# Polarfire SoC register map
Vendor: Microchip; File version: 1.0
CPU: Microchip PolarFire SoC 1.0, little endian
Registers are 32-bit, read-write, reset 0x0 unless marked. A register's access mark holds for its fields unless they carry their own. Offsets are from the block's base; [hi:lo] are bit positions.

## MMUART0_LO — MMUART0_LO Controller
Base 0x20000000
Same registers: MMUART1_LO 0x20100000, MMUART2_LO 0x20102000, MMUART3_LO 0x20104000, MMUART4_LO 0x20106000, MMUART0_HI 0x28000000, MMUART1_HI 0x28100000, MMUART2_HI 0x28102000, MMUART3_HI 0x28104000, MMUART4_HI 0x28106000
0x00 RBR ro — Receiver buffer register
  [7:0] RBR — This register holds the receive data bits for MMUART_x. The default value is unknown since the register is loaded with data in the receive FIFO. Bit 0 is the LSB and it is the first bit received. It may be configured as the MSB by configuring the E_MSB_RX bit in the MM1. The divisor latch access bit (DLAB).. bit 7 of LCR.. must be 0 to read this register. This register is read only. Writing to this register with the DLAB 0 changes the transmit holding register (THR) register value.
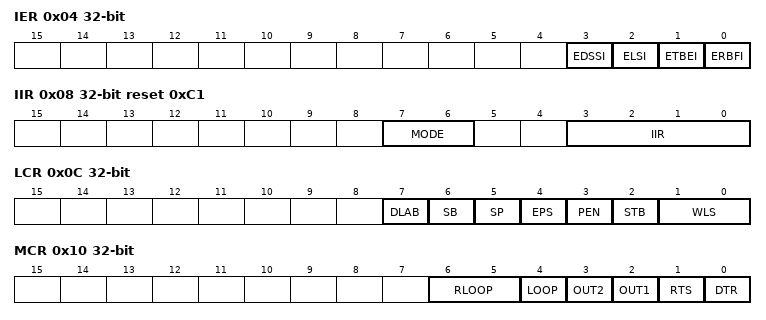
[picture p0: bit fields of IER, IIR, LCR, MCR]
0x04 IER — Interrupt enable register
  [3] EDSSI — Modem status interrupt enable 0: Disabled (default) 1: Enabled
  [2] ELSI — Receiver line status interrupt enable 0: Disabled (default) 1: Enabled
  [1] ETBEI — Transmitter holding register empty interrupt enable 0: Disabled (default) 1: Enabled
  [0] ERBFI — Enables received data available interrupt 0: Disabled (default) 1: Enabled
0x08 IIR ro reset 0xC1 — Interrupt identification register
  [7:6] MODE — Always 0b11. Enables FIFO mode.
  [3:0] IIR — Interrupt identification bits. 0b0110: Highest priority. Receiver line status interrupts due to overrun error.. parity error.. framing error.. or break interrupt. Reading the line status register resets this interrupt. 0b0100: Second priority. Receive data available interrupt modem status interrupt. Reading the receiver buffer register (RBR) or the FIFO drops below the trigger level resets this interrupt. 0b1100: Second priority. Character timeout indication interrupt occurs when no characters have been read from the Rx FIFO during the last four character times and there was at least one character in it during this time. Reading the RBR resets this interrupt. 0b0010: Third priority. Transmit holding register empty interrupt. Reading the IIR or writing to the transmit holding register (THR) resets the interrupt. 0b0000: Fourth priority. Modem status interrupt due to clear to send.. data set ready.. ring indicator.. or data carrier detect being asserted. Reading the modem status register resets this interrupt. 0b0011: Fifth priority. Multi-mode interrupts can occur due to any of the interrupts mentioned in IIM. For more details refer to Table 12-15.
0x0C LCR — Line control register
  [7] DLAB — Divisor latch access bit. Enables access to the divisor latch registers during read or write operation to address 0 and 1. 0: Disabled (default) 1: Enabled
  [6] SB — Set break. Enabling this bit sets MMUART_x_TXD to 0. This does not have any effect on transmitter logic. The break is disabled by setting the bit to 0. 0: Disabled (default) 1: Set break
  [5] SP — Stick parity 0: Disabled (default) 1: Enabled When stick parity is enabled.. the parity is set according to bits [4:3] as follows: 11: 0 will be sent as a parity bit and checked when receiving. 01: 1 will be sent as a parity bit and checked when receiving.
  [4] EPS — Even parity select 0: Odd parity (default) 1: Even parity
  [3] PEN — Parity enable 0: Disabled 1: Enabled. Parity is added in transmission and checked in receiving.
  [2] STB — Number of stop bits (STB) 0: 1 stop bit (default) 1: 11/2 stop bits when WLS=00 The number of stop bits is 2 for all other cases not described above (STB=1 and WLS=01.. 10.. or 11).
  [1:0] WLS — Word length select 0b00: 5 bits (default) 0b01: 6 bits 0b10: 7 bits 0b11: 8 bits
0x10 MCR — Modem control register
  [6:5] RLOOP — Remote loopback enable bits. In the Remote loopback mode.. when a bit is received.. it is sent directly out the transmit line.. bypassing the transmitter block.. and disabling the receiver. In the Automatic echo mode.. when a bit is received.. it is sent directly out the transmit line.. bypassing the transmitter block.. while the receiver is still enabled. 00: Disabled (default) 01: Remote loopback enabled 10: Automatic echo enabled 11: Reserved Note: Local loopback mode has priority over the remote/echo loopback modes.
  [4] LOOP — In the Loopback mode.. MMUART_x_TXD is set to 1. The MMUART_x_RXD.. MMUART_x_DSR.. MMUART_x_CTS.. MMUART_x_RI.. and MMUART_x_DCD inputs are disconnected. The output of the transmitter shift register is looped back into the receiver shift register. The modem control outputs (MMUART_x_DTR.. MMUART_x_RTS.. MMUART_x_OUT1.. and MMUART_x_OUT2) are connected internally to the modem control inputs.. and the modem control output pins are set as 1. The transmitted data is immediately received.. allowing Cortex-M3 processor to check the operation of the MMUART_x. The interrupts are operating in the Loopback mode. 0: Disabled (default) 1: Local loopback enabled Note: The local loopback mode has priority over the remote loopback modes. LOOPBACK is only implemented in basic UART mode. It does function in LIN IRDA or Smart card modes.
  [3] OUT2 — Controls the output2 (OUT2) signal. Active Low 0: OUT2n is less than equal to 1 (default) 1: OUT2n is less than equal to 0
  [2] OUT1 — Controls the output1 (OUT1) signal. Active Low 0: OUT1n is less than equal to 1 (default) 1: OUT1n is less than equal to 0
  [1] RTS — Controls the request to send (MMUART_x_RTS) signal. Active Low 0: RTSn is less than equal to 1 (default) 1: RTSn is less than equal to 0
  [0] DTR — Data terminal ready (MMUART_x_DTR) output. Active Low 0: DTRn is less than or equal to 1 (default) 1: DTRn is less than or equal to 0
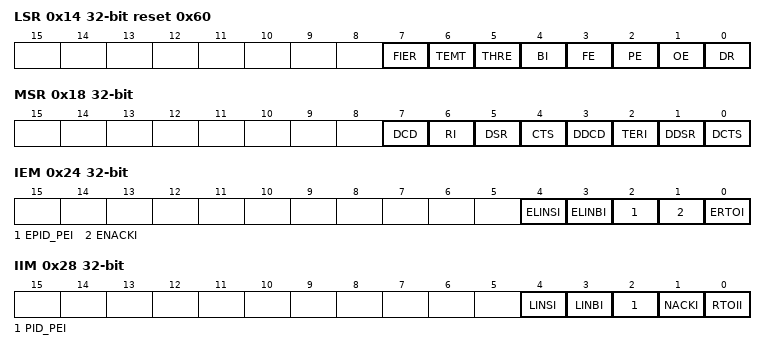
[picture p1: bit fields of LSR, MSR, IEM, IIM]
0x14 LSR ro reset 0x60 — Line status register
  [7] FIER — This bit is set when there is at least one parity error.. framing error.. or break indication in the FIFO. FIER is cleared when Cortex-M3 processor reads the LSR.. if there are no subsequent errors in the FIFO.
  [6] TEMT — Transmit empty (TEMT). This bit is set to 1 when both the transmitter FIFO and shift registers are empty.
  [5] THRE — Transmitter holding register empty (THRE). Indicates that the MMUART_x is ready to transmit a new data byte. THRE causes an interrupt to the Cortex-M3 processor when bit 1 (ETBEI) in the interrupt enable register is 1. This bit is set when the Tx FIFO is empty. It is cleared when at least one byte is written to the Tx FIFO.
  [4] BI — Break interrupt (BI). Indicates that the receive data is at 0 longer than a full word transmission time (start bit + data bits + parity + stop bits). BI is cleared when Cortex-M3 processor reads the line status register (LSR). This error is revealed to the Cortex-M3 processor when it is associated character is at the top of the FIFO. When break occurs.. only one zero character is loaded into the FIFO.
  [3] FE — Framing error (FE). Indicates that the receive byte did not have a valid stop bit. FE is cleared when Cortex-M3 processor reads the LSR. The MMUART_x tries to resynchronize after a framing error. To do this.. it assumes that the framing error was due to the next start bit.. so it samples this start bit twice.. and then starts receiving the data. This error is revealed to Cortex-M3 processor when it is associated character is at the top of the FIFO.
  [2] PE — Parity error (PE). Indicates that the receive byte had a parity error. PE is cleared when the Cortex-M3 processor reads the LSR. This error is revealed to the Cortex-M3 processor when it is associated character is at the top of the FIFO.
  [1] OE — Overrun error (OE). Indicates that the new byte was received before the Cortex-M3 processor reads the byte from the receive buffer.. and that the earlier data byte was destroyed. OE is cleared when the Cortex-M3 processor reads the LSR. If the data continues to fill the FIFO beyond the trigger level.. an overrun error occurs once the FIFO is full and the next character has been completely received in the shift register. The character in the shift register is overwritten.. but it is not transferred to the FIFO.
  [0] DR — Data ready (DR). 1: Indicates when a data byte is received and stored in the receive buffer or the FIFO. DR is cleared to 0 when the Cortex-M3 processor reads the data from the receive buffer or the FIFO.
0x18 MSR ro — Modem status register
  [7] DCD — Data carrier detect (DCD) (MMUART_x_DCD).The complement of DCD input. When bit 4 of the MCR is set to 1 (loop).. this bit is equivalent to OUT2 in the MCR.
  [6] RI — Ring indicator (RI) (MMUART_x_RI). The complement of the RI input. When bit 4 of the MCR is set to 1 (loop).. this bit is equivalent to OUT1 in the MCR.
  [5] DSR — Data set ready (DSR) (MMUART_x_DSR). The complement of the DSR input. When bit 4 of the MCR is set to 1 (loop).. this bit is equivalent to RTS in the MCR.
  [4] CTS — Clear to send (CTS) (MMUART_x_CTS). The complement of the CTS input. When bit 4 of the MCR is set to 1 (loop).. this bit is equivalent to DTR in the MCR.
  [3] DDCD — Delta data carrier detect (DDCD) indicator. Indicates that DCD input has changed state. Whenever bit 0.. 1.. 2.. or 3 is set to 1.. a modem status interrupt is generated.
  [2] TERI — Trailing edge of ring indicator (TERI) detector. Indicates that RI input has changed from 0 to 1. Whenever bit 0.. 1.. 2.. or 3 is set to 1.. a modem status interrupt is generated.
  [1] DDSR — Delta data set ready (DDSR) indicator. Indicates that the DSRn input has changed state since the last time it was read by the Cortex-M3 processor. Whenever bit 0.. 1.. 2.. or 3 is set to 1.. a modem status interrupt is generated.
  [0] DCTS — Delta clear to send (DCTS) indicator. Indicates that the CTSn input has changed state since the last time it was read by the Cortex-M3 processor. Whenever bit 0.. 1.. 2.. or 3 is set to 1.. a modem status interrupt is generated.
0x1C SR — Scratch register
  [7:0] SCR — Scratch register. This register has no effect on MMUART_x operation.
0x24 IEM — Multi-mode interrupt enable register
  [4] ELINSI — Enables the LIN sync detection interrupt. 0: Disabled (default) 1: Enabled
  [3] ELINBI — Enables LIN break interrupt. 0: Disabled (default) 1: Enabled
  [2] EPID_PEI — Enables PID parity error interrupt 0: Disabled (default) 1: Enabled
  [1] ENACKI — Enables NACK interrupt. 0: Disabled (default) 1: Enabled
  [0] ERTOI — Enables receiver timeout interrupt. 0: Disabled (default) 1: Enabled
0x28 IIM ro — Multi-mode interrupt identification register
  [4] LINSI rw — LIN sync detection interrupt ID. This bit set when 5th falling edge is detected by the sync timer. It resets the FIFO address pointers so that the PID will be in the first location. Reading the IIM register clears this interrupt.
  [3] LINBI rw — LIN break interrupt.. set automatically when break length of 11.5 Tbits is detected. Reading the IIM register clears this interrupt.
  [2] PID_PEI — Protected identifier field (PID) parity error interrupt is generated when there is a mismatch in PID in LIN header.. that is.. when either the P0 or P1 bits in the incoming PID byte do not match the calculated P0 and P1 error.
  [1] NACKI rw — NACK interrupt is asserted when EERR bit is set in MM2. Reading the MM2 clears the interrupt.
  [0] RTOII — Receiver time-out (RTO) interrupt ID. RTO interrupt is asserted when RTO value is reached by the counter. It gets cleared when writing to the RTO register.
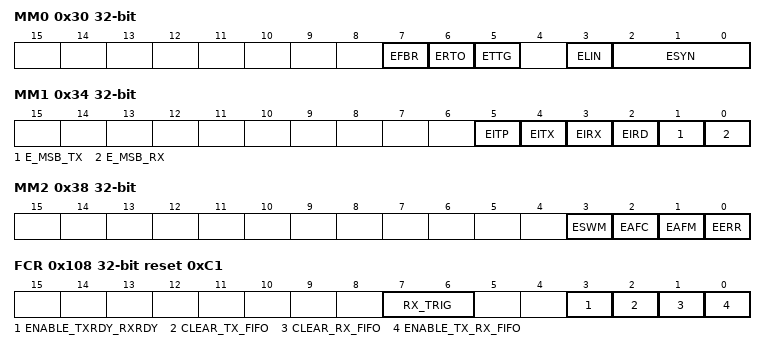
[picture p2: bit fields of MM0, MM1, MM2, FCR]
0x30 MM0 — Multi-mode control register0
  [7] EFBR — Enable fractional baud rate (FBR) mode. 0: Disabled (default) 1: Enabled
  [6] ERTO — Enable receiver timeout (RTO). Writing this bit enables the timeout and restarts the counter value. The timeout value is determined by the RTO register. 0: Disabled (default) 1: Enabled
  [5] ETTG — Enable transmitter time guard (TTG). The time guard value is determined by the TTG Register. 0: Disabled (default) 1: Enabled
  [3] ELIN — Enable LIN header detection and automatic baud rate calculation. 0: Disabled (default) 1: Enabled
  [2:0] ESYN — Enable synchronous operation. There are four types of Synchronous Operation modes that can be enabled. 0b000: Disabled.. that is.. Asynchronous mode (default) 0b001: Synchronous slave enabled.. positive-edge clock 0b010: Synchronous slave enabled.. negative-edge clock 0b011: Synchronous master enabled.. positive-edge clock 0b100: Synchronous master enabled.. negative-edge clock 0b101.. 0b110.. and 0b111: Reserved
0x34 MM1 — Multi-mode control register1
  [5] EITP — Output pulse width for RZI mod can be modified using this bit. 0: 3/16th Tbit pulse width (default). 1: 1/4th Tbit pulse width.
  [4] EITX — You can configure output polarity for RZI modulation. 0: RZI output pulses are active Low and signify a low NRZ value (default). 1: RZI output pulses are active High and signify a high NRZ value.
  [3] EIRX — You can configure input polarity for RZI demodulation. 0: RZI input pulses are active Low.. signifying a low NRZ value (default). 1: RZI input pulses are active High.. signifying a high NRZ value.
  [2] EIRD — Enables RZI modulation/demodulation. 0: Disabled (default) 1: Enabled
  [1] E_MSB_TX — LSB or MSB can be sent first by configuring this bit. By default.. the "THR" bit 0 is the LSB.. and is the first transmitted bit. Bit 0 of the THR may be configured as the last transmitted bit.. MSB. 0: THR's bit 0 is the first transmitted bit.(LSB). (default). 1: THR's bit 0 is the last transmitted bit.(MSB).
  [0] E_MSB_RX — LSB or MSB can be received first by configuring this bit. By default.. the receiver buffer register's (RBR) bit 0 is the LSB.. and is the first received bit. Bit 0 of the RBR may be configured as the last received bit.. MSB. 0: RBR's bit 0 is the first received bit(LSB). (default). 1: RBR's bit 0 is the last received bit(MSB).
0x38 MM2 — Multi-mode control register2
  [3] ESWM — Enable single-wire.. half-duplex mode. 0: Disabled (default) 1: Enabled
  [2] EAFC — Enable a address flag clear (EAFC). When EAFM is enabled the Rx FIFO is disabled until another address flag with matching address is received. The bit gets cleared on write in multi-mode control registers 2. 0: Disabled (default) 1: Enabled
  [1] EAFM — Enable automatic 9-bit address flag mode (EAFM). It should be noted that for enabling this bit it requires.. the LCR should be in an 8-bit and stick parity (SP) bit configured to 0. If EAFM bit is disabled.. the Rx FIFO is enabled by receiving all the bytes. When EAFM bit is enabled.. the Rx FIFO is disabled until an address flag with matching address is received. Note: If an address match occurs and the Rx FIFO is enabled then it can be disabled.. if either another address flag occurs or there is a mismatch or the EAFC bit is set. In either case.. the Address flag compare will continue as long as the EAFM bit is set. 0: Disabled (default) 1: Enabled
  [0] EERR — When the EERR bit is set.. the receiver forces an error signal transmit out.. if an incoming parity error is detected. Error signal (ACK/NACK) is sent during stop time enable. Note: The EERR only applies in an 8-bit data length.. 2 stop bit configuration. Error signal occurs during the last 1.5 stop bits as per Figure 12-18 on page 529. 0: Disabled (default) 1: Enabled
0x3C DFR — Fractional divisor register
  [5:0] DFR — The fractional divisor register (DFR) is used to store the fractional divisor used to calculate the fractional baud rate value in 1/64th using EQ 5. 0x0: 0/64 0x1: 1/64 .... 0x3F: 63/64
0x44 GFR — Glitch filter register
  [2:0] GLR — The glitch filter resynchronizes (GLR) and suppresses random input noise from MMUART_x_RXD (serial input data) and MMUART_x_SCK_IN (serial input clock in synchronous mode) based on the filter length given in number system clock cycles. The following are the different filter lengths in the APB clock cycles that can be written into the GLR register and their description. 0b000: Two resynchronize flip-flops are used but there is no spike suppression. 0b001: Three resynchronize flip-flops are used but there is no spike suppression. 0b010: Three resynchronize flip-flops are used and it also causes 1 APB clock cycle suppression. 0b011: Three resynchronize flip-flops are used and it also causes 2 APB clock cycle suppression. 0b100: Three resynchronize flip-flops are used and it also causes 3 APB clock cycle suppression. 0b101: Three resynchronize flip-flops are used and it also causes 4 APB clock cycle suppression. 0b110: Three resynchronize flip-flops are used and it also causes 5 APB clock cycle suppression. 0b111: Three resynchronize flip-flops are used and it also causes 6 APB clock cycle suppression.
0x48 TTG — Transmitter time guard register
  [7:0] TTG — If the transmitter time guard is enabled from the multi-mode control register 0 (MM0).. the transmitter time guard value determines the amount of system clock cycles to wait between transmissions. The time guard equation is based on the baud rate bit time (Tbit) value as follows: Tx Time Guard Value = TTG x Bit Time (Tbit)
0x4C RTO — Receiver time-out register
  [7:0] RTO — Writing to the RTO register sets the counter value and enables.. if the ERTO bit in the MM0 is enabled. You can configure the timeout value by writing into this register. The RTO counts when the Rx block input state is idle; is reset when a start condition occurs.. and restarts counting upon returning to the idle state. When the RTO value is reached.. the RTOII interrupt is set. Re-writing the RTO register clears the interrupt and sets the counter. The receiver timeout value equation is based on the baud rate bit time (Tbit) as follows: Rx Timeout Value = 4 x RTO x Bit Time (Tbit)
0x50 ADR — Address register
  [7:0] ADR — The address register is used in 9-bit Address Flag mode. When an address flag is received on the 9th bit.. and EAFM is set in MM2.. the incoming data is checked against the address register. If a match occurs.. the Rx FIFO is enabled.
0x80 DLR reset 0x1 — Divisor latch (LSB)
  [7:0] DLR — This divisor latch LSB register (DLR) holds the LSB of the integer divisor value used to calculate the baud rate. The baud rate can be calculated using EQ 1.. 2.. 3.. or 4. ** To access this Register DAP (bit7) of Line Control Register (LCR) should be set.
0x84 DMR — Divisor latch (MSB)
  [7:0] DMR — This divisor latch MSB register (DMR) holds the MSB of the integer divisor value used to calculate the baud rate. The baud rate can be calculated using EQ 1.. 2.. 3.. or 4. ** To access this Register DAP (bit7) of Line Control Register (LCR) should be set.
0x100 THR — Transmit holding register
  [7:0] THR — This register holds the data bits to be transmitted. Bit 0 is the LSB and is transmitted first. The MSB may be transmitted first.. if it is configured with the E_MSB_TX bit in the MM1. The reset value is unknown since the register is loaded with data in the transmit FIFO. The DLAB.. bit 7 of LCR.. must be 0 to write to this register. This register is write only. Reading from this register with the DLAB 0 reads the RBR register value.
0x108 FCR ro reset 0xC1 — FIFO control register
  [7:6] RX_TRIG rw — These bits are used to set the trigger level for the Rx FIFO interrupt. Rx FIFO trigger level (bytes) are: 0b00: 1 byte 0b01: 4 bytes 0b10: 8 bytes 0b11: 14 bytes
  [3] ENABLE_TXRDY_RXRDY rw — Switches between RXRDY and TXRDY mode 0 and mode 1 functionality. 0-Mode 0. 1-Mode 1
  [2] CLEAR_TX_FIFO rw — Clears all bytes in the Tx FIFO and resets its counter logic. The shift register is not cleared. 0: Disabled (default) 1: Enabled
  [1] CLEAR_RX_FIFO rw — Clears all bytes in Rx FIFO and resets counter logic. This shift register is not cleared. 0: Disabled (default) 1: Enabled
  [0] ENABLE_TX_RX_FIFO rw — It enables both the Tx and Rx FIFOs and is hardwired to 1.. which means it is always enabled and cannot be changed.
